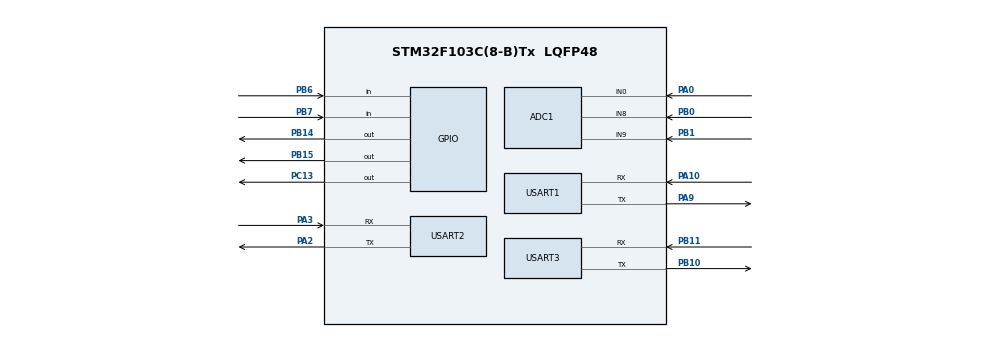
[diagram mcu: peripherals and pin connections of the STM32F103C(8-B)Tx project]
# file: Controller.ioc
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ADC1.Channel-2\#ChannelRegularConversion=ADC_CHANNEL_9
ADC1.Channel-4\#ChannelRegularConversion=ADC_CHANNEL_8
ADC1.Channel-5\#ChannelRegularConversion=ADC_CHANNEL_0
ADC1.DiscontinuousConvMode=ENABLE
ADC1.ExternalTrigConv=ADC_SOFTWARE_START
ADC1.NbrOfConversion=3
ADC1.NbrOfConversionFlag=1
ADC1.Rank-2\#ChannelRegularConversion=1
ADC1.Rank-4\#ChannelRegularConversion=2
ADC1.Rank-5\#ChannelRegularConversion=3
ADC1.SamplingTime-2\#ChannelRegularConversion=ADC_SAMPLETIME_1CYCLE_5
ADC1.SamplingTime-4\#ChannelRegularConversion=ADC_SAMPLETIME_1CYCLE_5
ADC1.SamplingTime-5\#ChannelRegularConversion=ADC_SAMPLETIME_1CYCLE_5
ADC1.master=1
Mcu.Family=STM32F1
Mcu.Name=STM32F103C(8-B)Tx
Mcu.Package=LQFP48
NVIC.ADC1_2_IRQn=true\:3\:0\:true\:false\:true\:true\:true\:true
NVIC.PriorityGroup=NVIC_PRIORITYGROUP_4
NVIC.TIM3_IRQn=true\:2\:0\:true\:false\:true\:true\:true\:true
NVIC.USART2_IRQn=true\:0\:0\:true\:false\:true\:true\:true\:true
NVIC.USART3_IRQn=true\:1\:0\:true\:false\:true\:true\:true\:true
PA0-WKUP.Signal=ADCx_IN0
PA10.Mode=Asynchronous
PA10.Signal=USART1_RX
PA13.Mode=Serial_Wire
PA13.Signal=SYS_JTMS-SWDIO
PA14.Mode=Serial_Wire
PA14.Signal=SYS_JTCK-SWCLK
PA2.Mode=Asynchronous
PA2.Signal=USART2_TX
PA3.Mode=Asynchronous
PA3.Signal=USART2_RX
PA9.Mode=Asynchronous
PA9.Signal=USART1_TX
PB0.Signal=ADCx_IN8
PB1.Signal=ADCx_IN9
PB10.Mode=Asynchronous
PB10.Signal=USART3_TX
PB11.Mode=Asynchronous
PB11.Signal=USART3_RX
PB14.GPIO_ModeDefaultOutputPP=GPIO_MODE_OUTPUT_OD
PB14.GPIO_PuPd=GPIO_NOPULL
PB14.Signal=GPIO_Output
PB15.GPIO_ModeDefaultOutputPP=GPIO_MODE_OUTPUT_OD
PB15.GPIO_PuPd=GPIO_NOPULL
PB15.Signal=GPIO_Output
PB6.GPIO_PuPd=GPIO_PULLDOWN
PB6.Signal=GPIO_Input
PB7.GPIO_PuPd=GPIO_PULLDOWN
PB7.Signal=GPIO_Input
PC13-TAMPER-RTC.Signal=GPIO_Output
ProjectManager.HeapSize=0x200
ProjectManager.StackSize=0x400
ProjectManager.TargetToolchain=MDK-ARM V5.32
RCC.APB1Freq_Value=8000000
RCC.APB2Freq_Value=8000000
SH.ADCx_IN0.0=ADC1_IN0,IN0
SH.ADCx_IN8.0=ADC1_IN8,IN8
SH.ADCx_IN9.0=ADC1_IN9,IN9
TIM3.AutoReloadPreload=TIM_AUTORELOAD_PRELOAD_ENABLE
TIM3.Period=999
TIM3.Prescaler=799
TIM3.TIM_MasterOutputTrigger=TIM_TRGO_UPDATE
TIM3.TIM_MasterSlaveMode=TIM_MASTERSLAVEMODE_DISABLE
USART1.VirtualMode=VM_ASYNC
USART2.VirtualMode=VM_ASYNC
USART3.VirtualMode=VM_ASYNC
VP_TIM3_VS_ClockSourceINT.Mode=Internal
board=custom

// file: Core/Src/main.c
/* USER CODE BEGIN Header */
/**
  ******************************************************************************
  * @file           : main.c
  * @brief          : Main program body
  ******************************************************************************
  * @attention
  *
  * Copyright (c) 2025 STMicroelectronics.
  * All rights reserved.
  *
  * This software is licensed under terms that can be found in the LICENSE file
  * in the root directory of this software component.
  * If no LICENSE file comes with this software, it is provided AS-IS.
  *
  ******************************************************************************
  */
/* USER CODE END Header */
#include "main.h"
#include "adc.h"
#include "tim.h"
#include "usart.h"
#include "gpio.h"

/* USER CODE BEGIN Includes */
#include "OLED.h"
#include "func.h"
#include "string.h"
/* USER CODE END Includes */

/* USER CODE BEGIN PV */
extern uint8_t rx_uart2[2];
extern int command;
/* USER CODE END PV */

void SystemClock_Config(void);

int main(void)
{

  /* MCU Configuration--------------------------------------------------------*/

  /* Reset of all peripherals, Initializes the Flash interface and the Systick. */
  HAL_Init();

  /* Configure the system clock */
  SystemClock_Config();

  /* Initialize all configured peripherals */
  MX_GPIO_Init();
  MX_USART1_UART_Init();
  MX_ADC1_Init();
  MX_TIM3_Init();
  MX_USART3_UART_Init();
  MX_USART2_UART_Init();
  /* USER CODE BEGIN 2 */

  OLED_Init();
	LED_Init();
	HAL_TIM_Base_Start_IT(&htim3);
  HAL_UART_Transmit(&huart2,(uint8_t*)"done",sizeof("done"),HAL_MAX_DELAY);
	HAL_UART_Receive_IT(&huart2,rx_uart2,2);
  /* USER CODE END 2 */

  /* Infinite loop */
  /* USER CODE BEGIN WHILE */
  while (1)
  {
    uint8_t rxspeed[2]={0,0};
		HAL_UART_Receive(&huart3,rxspeed,2,HAL_MAX_DELAY);
    HAL_UART_Transmit(&huart2,rxspeed,2,HAL_MAX_DELAY);
    /* USER CODE END WHILE */

  }
}

void SystemClock_Config(void)
{
  RCC_OscInitTypeDef RCC_OscInitStruct = {0};
  RCC_ClkInitTypeDef RCC_ClkInitStruct = {0};
  RCC_PeriphCLKInitTypeDef PeriphClkInit = {0};

  /** Initializes the RCC Oscillators according to the specified parameters
  * in the RCC_OscInitTypeDef structure.
  */
  RCC_OscInitStruct.OscillatorType = RCC_OSCILLATORTYPE_HSI;
  RCC_OscInitStruct.HSIState = RCC_HSI_ON;
  RCC_OscInitStruct.HSICalibrationValue = RCC_HSICALIBRATION_DEFAULT;
  RCC_OscInitStruct.PLL.PLLState = RCC_PLL_NONE;
  if (HAL_RCC_OscConfig(&RCC_OscInitStruct) != HAL_OK)
  {
    Error_Handler();
  }

  /** Initializes the CPU, AHB and APB buses clocks
  */
  RCC_ClkInitStruct.ClockType = RCC_CLOCKTYPE_HCLK|RCC_CLOCKTYPE_SYSCLK
                              |RCC_CLOCKTYPE_PCLK1|RCC_CLOCKTYPE_PCLK2;
  RCC_ClkInitStruct.SYSCLKSource = RCC_SYSCLKSOURCE_HSI;
  RCC_ClkInitStruct.AHBCLKDivider = RCC_SYSCLK_DIV1;
  RCC_ClkInitStruct.APB1CLKDivider = RCC_HCLK_DIV1;
  RCC_ClkInitStruct.APB2CLKDivider = RCC_HCLK_DIV1;

  if (HAL_RCC_ClockConfig(&RCC_ClkInitStruct, FLASH_LATENCY_0) != HAL_OK)
  {
    Error_Handler();
  }
  PeriphClkInit.PeriphClockSelection = RCC_PERIPHCLK_ADC;
  PeriphClkInit.AdcClockSelection = RCC_ADCPCLK2_DIV2;
  if (HAL_RCCEx_PeriphCLKConfig(&PeriphClkInit) != HAL_OK)
  {
    Error_Handler();
  }
}

void Error_Handler(void)
{
  __disable_irq();
  while (1)
  {
  }
}
